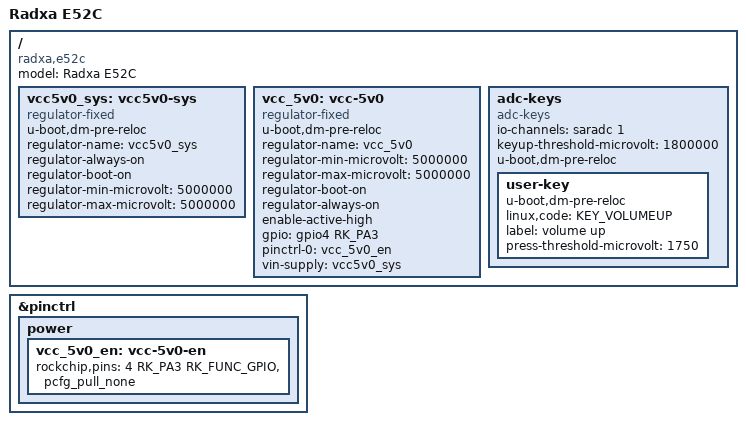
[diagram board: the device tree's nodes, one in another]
// SPDX-License-Identifier: (GPL-2.0+ OR MIT)
/*
 * Copyright (c) 2021 Rockchip Electronics Co., Ltd
 *
 */

/dts-v1/;
#include "rk3588.dtsi"
#include "rk3588-u-boot.dtsi"
#include <dt-bindings/input/input.h>

/ {
	model = "Radxa E52C";
	compatible = "radxa,e52c", "rockchip,rk3588";

	vcc5v0_sys: vcc5v0-sys {
		u-boot,dm-pre-reloc;
		compatible = "regulator-fixed";
		regulator-name = "vcc5v0_sys";
		regulator-always-on;
		regulator-boot-on;
		regulator-min-microvolt = <5000000>;
		regulator-max-microvolt = <5000000>;
	};

	vcc_5v0: vcc-5v0 {
		u-boot,dm-pre-reloc;
		compatible = "regulator-fixed";
		regulator-name = "vcc_5v0";
		regulator-min-microvolt = <5000000>;
		regulator-max-microvolt = <5000000>;
		regulator-boot-on;
		regulator-always-on;
		enable-active-high;
		gpio = <&gpio4 RK_PA3 GPIO_ACTIVE_HIGH>;
		pinctrl-names = "default";
		pinctrl-0 = <&vcc_5v0_en>;
		vin-supply = <&vcc5v0_sys>;
	};

	adc-keys {
		compatible = "adc-keys";
		io-channels = <&saradc 1>;
		io-channel-names = "buttons";
		keyup-threshold-microvolt = <1800000>;
		u-boot,dm-pre-reloc;
		status = "okay";

		user-key {
			u-boot,dm-pre-reloc;
			linux,code = <KEY_VOLUMEUP>;
			label = "volume up";
			press-threshold-microvolt = <1750>;
		};
	};
};

&pinctrl {
	power {
		u-boot,dm-spl;
		vcc_5v0_en: vcc-5v0-en {
			u-boot,dm-spl;
			rockchip,pins = <4 RK_PA3 RK_FUNC_GPIO &pcfg_pull_none>;
		};
	};
};
